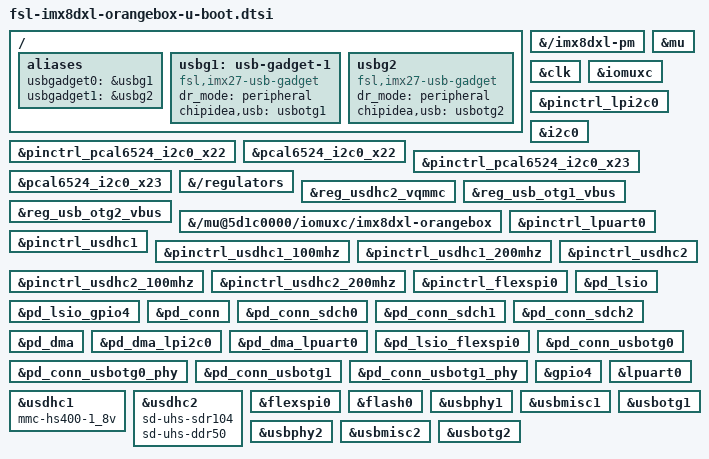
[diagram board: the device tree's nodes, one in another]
// SPDX-License-Identifier: GPL-2.0+
/*
 * Copyright 2022 NXP
 */

/ {
	aliases {
		usbgadget0 = &usbg1;
		usbgadget1 = &usbg2;
	};

	usbg1: usb-gadget-1 {
		compatible = "fsl,imx27-usb-gadget";
		dr_mode = "peripheral";
		chipidea,usb = <&usbotg1>;
		status = "okay";
		bootph-pre-ram;
	};

	usbg2: usbg2 {
		compatible = "fsl,imx27-usb-gadget";
		dr_mode = "peripheral";
		chipidea,usb = <&usbotg2>;
		status = "okay";
		bootph-pre-ram;
	};
};

&{/imx8dxl-pm} {
	bootph-some-ram;
	bootph-pre-ram;
};

&mu {
	bootph-some-ram;
	bootph-pre-ram;
};

&clk {
	bootph-some-ram;
	bootph-pre-ram;
};

&iomuxc {
	bootph-some-ram;
	bootph-pre-ram;
};

&pinctrl_lpi2c0 {
	bootph-pre-ram;
};

&i2c0 {
	bootph-pre-ram;
};

&pinctrl_pcal6524_i2c0_x22 {
	bootph-pre-ram;
};

&pcal6524_i2c0_x22 {
	bootph-pre-ram;
};

&pinctrl_pcal6524_i2c0_x23 {
	bootph-pre-ram;
};

&pcal6524_i2c0_x23 {
	bootph-pre-ram;
};

&{/regulators} {
	bootph-pre-ram;
};

&reg_usdhc2_vqmmc {
	bootph-pre-ram;
};

&reg_usb_otg1_vbus {
	bootph-pre-ram;
};

&reg_usb_otg2_vbus {
	bootph-pre-ram;
};

&{/mu@5d1c0000/iomuxc/imx8dxl-orangebox} {
	bootph-some-ram;
	bootph-pre-ram;
};

&pinctrl_lpuart0 {
	bootph-some-ram;
	bootph-pre-ram;
};

&pinctrl_usdhc1 {
	bootph-pre-ram;
};

&pinctrl_usdhc1_100mhz {
	bootph-pre-ram;
};

&pinctrl_usdhc1_200mhz {
	bootph-pre-ram;
};

&pinctrl_usdhc2 {
	bootph-pre-ram;
};

&pinctrl_usdhc2_100mhz {
	bootph-pre-ram;
};

&pinctrl_usdhc2_200mhz {
	bootph-pre-ram;
};

&pinctrl_flexspi0 {
	bootph-pre-ram;
};

&pd_lsio {
	bootph-pre-ram;
};

&pd_lsio_gpio4 {
	bootph-pre-ram;
};

&pd_conn {
	bootph-pre-ram;
};

&pd_conn_sdch0 {
	bootph-pre-ram;
};

&pd_conn_sdch1 {
	bootph-pre-ram;
};

&pd_conn_sdch2 {
	bootph-pre-ram;
};

&pd_dma {
	bootph-some-ram;
	bootph-pre-ram;
};

&pd_dma_lpi2c0 {
	bootph-pre-ram;
};

&pd_dma_lpuart0 {
	bootph-some-ram;
	bootph-pre-ram;
};

&pd_lsio_flexspi0 {
	bootph-pre-ram;
};

&pd_conn_usbotg0 {
	bootph-pre-ram;
};

&pd_conn_usbotg0_phy {
	bootph-pre-ram;
};

&pd_conn_usbotg1 {
	bootph-pre-ram;
};

&pd_conn_usbotg1_phy {
	bootph-pre-ram;
};

&gpio4 {
	bootph-pre-ram;
};

&lpuart0 {
	bootph-some-ram;
	bootph-pre-ram;
};

&usdhc1 {
	bootph-pre-ram;
	mmc-hs400-1_8v;
};

&usdhc2 {
	bootph-pre-ram;
	sd-uhs-sdr104;
	sd-uhs-ddr50;
};

&flexspi0 {
	bootph-pre-ram;
};

&flash0 {
	bootph-pre-ram;
};

&usbphy1 {
	bootph-pre-ram;
};

&usbmisc1 {
	bootph-pre-ram;
};

&usbotg1 {
	bootph-pre-ram;
};

&usbphy2 {
	bootph-pre-ram;
};

&usbmisc2 {
	bootph-pre-ram;
};

&usbotg2 {
	bootph-pre-ram;
};
